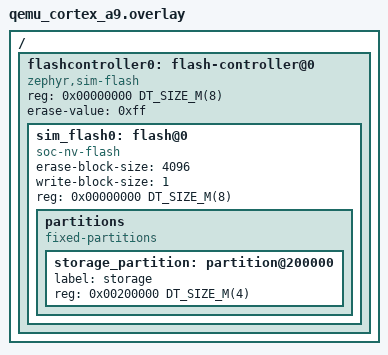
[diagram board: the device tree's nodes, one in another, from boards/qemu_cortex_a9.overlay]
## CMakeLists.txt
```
# SPDX-License-Identifier: GPL-3.0-or-later
# The Zephyr test program: the platform layer's conformance suite and the 615A engine tests,
# run by Catch2 on Zephyr. Built with west or cmake as any Zephyr application is, for native_sim
# in CI (docs/building.md, docs/testing.md); this is the Zephyr counterpart of the
# adl_platform_tests and adl_engine_tests programs of tests/CMakeLists.txt, and runs the same
# source files:
#
#   west build -b native_sim/native/64 tests/platform/zephyr -- -DZEPHYR_EXTRA_MODULES=$PWD
#
# The repository is a Zephyr module (zephyr/module.yml) that builds the platform layer and the
# libraries; this application supplies Catch2, a main, and the board's file system.
cmake_minimum_required(VERSION 3.20.0)

get_filename_component(ADL_REPO_ROOT "${CMAKE_CURRENT_LIST_DIR}/../../.." ABSOLUTE)
list(APPEND ZEPHYR_EXTRA_MODULES "${ADL_REPO_ROOT}")

find_package(Zephyr REQUIRED HINTS $ENV{ZEPHYR_BASE})
project(adl_zephyr_tests LANGUAGES C CXX)

# Catch2, the version the vcpkg baseline of the other platforms resolves to. A source tree can
# be named with -DFETCHCONTENT_SOURCE_DIR_CATCH2=<dir> for a build without network access.
include(FetchContent)
FetchContent_Declare(Catch2
    URL https://github.com/catchorg/Catch2/archive/refs/tags/v3.15.3.tar.gz
    URL_HASH SHA256=b0299ae552918220a7a6e21e7de5b714777f4e8c883fb70c4bb23fe01df8c6e3
    DOWNLOAD_EXTRACT_TIMESTAMP TRUE)
set(CATCH_INSTALL_DOCS OFF CACHE BOOL "" FORCE)
set(CATCH_INSTALL_EXTRAS OFF CACHE BOOL "" FORCE)
set(CATCH_DEVELOPMENT_BUILD OFF CACHE BOOL "" FORCE)
FetchContent_MakeAvailable(Catch2)

# Catch2 is built with Zephyr's flags like everything else (on a board those are the
# architecture's, not the host compiler's defaults), and where there is no host operating system
# under Zephyr (anything but native_sim) without Catch2's POSIX signal handlers.
target_link_libraries(Catch2 PRIVATE zephyr_interface)
if(NOT CONFIG_ARCH_POSIX)
    target_compile_definitions(Catch2 PUBLIC CATCH_CONFIG_NO_POSIX_SIGNALS)
endif()

# What the engine tests need beyond the module's libraries: the sample loads and the second
# TFTP implementation the simulated target is written with.
list(PREPEND CMAKE_MODULE_PATH "${ADL_REPO_ROOT}/cmake")
add_subdirectory("${ADL_REPO_ROOT}/libs/samples" adl_samples)
add_subdirectory("${ADL_REPO_ROOT}/libs/arinc615a_mini" adl_arinc615a_mini)

# Zephyr's flags for them, as the module gives its libraries (-std=c++23 in particular).
foreach(_lib IN ITEMS adl_samples adl_arinc615a_mini)
    target_link_libraries(${_lib} PRIVATE zephyr_interface)
    if(NOT CONFIG_ADL_WARNINGS_AS_ERRORS)
        target_link_libraries(${_lib} PRIVATE adl_zephyr_tolerant)
    endif()
endforeach()

# The sources and include directories the RTOS test programs share.
include("${ADL_REPO_ROOT}/tests/platform/rtos_support/test_sources.cmake")

target_sources(app PRIVATE
    src/main.cpp
    src/stack_storage_test.cpp
    ${ADL_RTOS_PLATFORM_TEST_SOURCES}
    ${ADL_RTOS_ENGINE_TEST_SOURCES})
target_include_directories(app PRIVATE ${ADL_RTOS_TEST_INCLUDES})
target_compile_definitions(app PRIVATE "ADL_TEST_SCRATCH_ROOT=\"/lfs\"")

target_link_libraries(app PRIVATE
    Catch2::Catch2
    adl::platform
    adl::arinc615a_runner
    adl::arinc615a
    adl::arinc665
    adl::arinc615a_mini
    adl::samples)
```

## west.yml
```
# The Zephyr workspace the native_sim test program is built in (tests/platform/zephyr,
# docs/building.md). `west init -l --mf tests/platform/zephyr/west.yml .` in the repository
# makes the directory above it the workspace; `west update` fetches Zephyr at the version the
# program is verified with, and only the modules it needs.
manifest:
  remotes:
    - name: zephyrproject-rtos
      url-base: https://github.com/zephyrproject-rtos
  projects:
    - name: zephyr
      remote: zephyrproject-rtos
      revision: v4.4.2
      import:
        name-allowlist:
          - cmsis      # Cortex-A (the qemu_cortex_a9 suite run); cmsis_6 is Cortex-M
          - cmsis_6
          - littlefs
  self:
    path: arinc-data-loader
```

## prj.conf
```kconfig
# C++23 with the host's standard library (native_sim links the host's libstdc++); Catch2 needs
# exceptions and RTTI.
CONFIG_CPP=y
CONFIG_STD_CPP23=y
CONFIG_REQUIRES_FULL_LIBCPP=y
CONFIG_CPP_EXCEPTIONS=y
CONFIG_CPP_RTTI=y

# Catch2 runs on the main thread, and the 615A engine tests build large buffers on it.
CONFIG_MAIN_STACK_SIZE=262144
CONFIG_HEAP_MEM_POOL_SIZE=4194304

# The platform layer under test.
CONFIG_ADL_PLATFORM=y
CONFIG_ADL_WARNINGS_AS_ERRORS=y
CONFIG_ADL_HEAP_BYTES=2097152
CONFIG_DYNAMIC_THREAD_ALLOC=y
CONFIG_ZVFS_POLL_MAX=64

# Files: littlefs on the simulated flash, mounted at /lfs by main.cpp.
CONFIG_FLASH=y
CONFIG_FLASH_MAP=y
CONFIG_FILE_SYSTEM=y
CONFIG_FILE_SYSTEM_MKFS=y
CONFIG_FILE_SYSTEM_LITTLEFS=y
CONFIG_FS_LITTLEFS_NUM_FILES=16
CONFIG_FS_LITTLEFS_NUM_DIRS=8
CONFIG_FS_LITTLEFS_CACHE_SIZE=512
CONFIG_FS_LITTLEFS_READ_SIZE=64
CONFIG_FS_LITTLEFS_PROG_SIZE=64
CONFIG_FS_LITTLEFS_LOOKAHEAD_SIZE=128
CONFIG_FS_LITTLEFS_FC_HEAP_SIZE=65536

# Network: Zephyr's own IPv4/UDP stack over its loopback interface, so that the tests need no
# tap device and no privilege. A 65468 byte datagram is one loopback packet.
CONFIG_NETWORKING=y
CONFIG_NET_IPV4=y
CONFIG_NET_IPV6=n
CONFIG_NET_UDP=y
CONFIG_NET_TCP=n
CONFIG_NET_DRIVERS=y
CONFIG_NET_LOOPBACK=y
CONFIG_NET_LOOPBACK_MTU=65535
CONFIG_NET_SOCKETS=y
CONFIG_NET_MAX_CONTEXTS=32
CONFIG_NET_MAX_CONN=32
CONFIG_NET_PKT_RX_COUNT=128
CONFIG_NET_PKT_TX_COUNT=128
CONFIG_NET_BUF_DATA_SIZE=1024
CONFIG_NET_BUF_RX_COUNT=600
CONFIG_NET_BUF_TX_COUNT=600
CONFIG_NET_LOG=n
```

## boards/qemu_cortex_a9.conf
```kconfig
# A Cortex-A9 under QEMU, built with the Zephyr SDK's GCC and picolibc: the same program as on
# native_sim, on a real architecture and C library.
CONFIG_PICOLIBC=y
CONFIG_COMMON_LIBC_MALLOC_ARENA_SIZE=33554432
CONFIG_TEST_RANDOM_GENERATOR=y
# GCC 14 at -O2 warns in the libraries (-Wnull-dereference on an inlined allocation).
CONFIG_ADL_WARNINGS_AS_ERRORS=n
# Catch2 and libstdc++'s streams ask the C library for open, read, write, fstat, gettimeofday...:
# Zephyr's POSIX layer answers.
CONFIG_POSIX_API=y
# The board runs with its MMU on, and the kernel's virtual address space (8 MB by default) has to
# hold the whole image: this one is 26 MB, mostly buffers, and without room device mappings panic
# before the console is up.
CONFIG_KERNEL_VM_SIZE=0x8000000
```

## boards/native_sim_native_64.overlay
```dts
/* The flash behind the test file system. native_sim's own is 2 MB with a 16 KB storage
 * partition; the conformance suite writes files of 300 KB, so the flash is made 8 MB and
 * the storage partition 4 MB of it. */

/delete-node/ &storage_partition;

&flashcontroller0 {
	reg = <0x00000000 DT_SIZE_M(8)>;
};

&flash0 {
	reg = <0x00000000 DT_SIZE_M(8)>;

	partitions {
		storage_partition: partition@200000 {
			label = "storage";
			reg = <0x00200000 DT_SIZE_M(4)>;
		};
	};
};
```

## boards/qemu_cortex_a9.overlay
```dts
/* A flash behind the test file system: Zephyr's flash simulator, a RAM array, 8 MB with a 4 MB
 * storage partition, as native_sim has (this board has no flash of its own). */

/ {
	flashcontroller0: flash-controller@0 {
		compatible = "zephyr,sim-flash";
		reg = <0x00000000 DT_SIZE_M(8)>;

		#address-cells = <1>;
		#size-cells = <1>;
		erase-value = <0xff>;

		sim_flash0: flash@0 {
			status = "okay";
			compatible = "soc-nv-flash";
			erase-block-size = <4096>;
			write-block-size = <1>;
			reg = <0x00000000 DT_SIZE_M(8)>;

			partitions {
				compatible = "fixed-partitions";
				#address-cells = <1>;
				#size-cells = <1>;

				storage_partition: partition@200000 {
					label = "storage";
					reg = <0x00200000 DT_SIZE_M(4)>;
				};
			};
		};
	};
};
```

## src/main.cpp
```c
// SPDX-License-Identifier: GPL-3.0-or-later
// The Zephyr test program: Catch2 run on Zephyr's main thread, over the real platform layer
// (libs/platform/zephyr) on whatever board the program is built for. CI builds it for
// native_sim, where Zephyr's kernel, network stack and file system run as a host process.
//
// Before Catch2 starts, the file system the conformance suite writes to is made and mounted:
// littlefs on the board's storage partition at /lfs, freshly formatted so that a run does not
// meet the files of the last. Catch2's arguments come from the environment variable
// ADL_CATCH_ARGS (a native_sim process has an environment and Zephyr's main has no argv):
//
//     ADL_CATCH_ARGS="[conformance] --durations yes" ./zephyr.exe

#include <zephyr/fs/fs.h>
#include <zephyr/fs/littlefs.h>
#include <zephyr/kernel.h>
#include <zephyr/storage/flash_map.h>

#include <catch2/catch_session.hpp>

#include <cstdio>
#include <cstdlib>
#include <string>
#include <vector>

FS_LITTLEFS_DECLARE_DEFAULT_CONFIG(scratch_storage);

namespace
{

fs_mount_t scratch_mount;

[[nodiscard]] bool mount_scratch_file_system()
{
    const auto partition = static_cast<uintptr_t>(DT_FIXED_PARTITION_ID(DT_NODELABEL(storage_partition)));
    if (const int error = fs_mkfs(FS_LITTLEFS, partition, &scratch_storage, 0); error != 0)
    {
        std::printf("fs_mkfs failed: %d\n", error);
        return false;
    }
    scratch_mount.type = FS_LITTLEFS;
    scratch_mount.mnt_point = "/lfs";
    scratch_mount.fs_data = &scratch_storage;
    scratch_mount.storage_dev = reinterpret_cast<void*>(partition);
    if (const int error = fs_mount(&scratch_mount); error != 0)
    {
        std::printf("fs_mount failed: %d\n", error);
        return false;
    }
    return true;
}

// Splits the environment variable on blanks; empty when it is not set.
[[nodiscard]] std::vector<std::string> catch_arguments()
{
    std::vector<std::string> arguments{"adl_zephyr_tests"};
    const char* text = std::getenv("ADL_CATCH_ARGS");
    if (text == nullptr)
    {
        return arguments;
    }
    std::string current;
    for (const char* c = text;; ++c)
    {
        if (*c == ' ' || *c == '\0')
        {
            if (!current.empty())
            {
                arguments.push_back(std::move(current));
                current.clear();
            }
            if (*c == '\0')
            {
                break;
            }
        }
        else
        {
            current.push_back(*c);
        }
    }
    return arguments;
}

} // namespace

int main()
{
    int status = 2;
    if (mount_scratch_file_system())
    {
        const std::vector<std::string> arguments = catch_arguments();
        std::vector<const char*> argv;
        for (const std::string& argument : arguments)
        {
            argv.push_back(argument.c_str());
        }
        Catch::Session session;
        status = session.run(static_cast<int>(argv.size()), argv.data());
    }
    std::fflush(stdout);
    // A native_sim process ends when it is told to, with the code the harness reads; on a
    // board there is nowhere to exit to, and this is the end of the program.
    std::exit(status);
}
```

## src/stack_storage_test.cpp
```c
// A test only Zephyr can run: a thread on a stack the caller made. The conformance suite spawns
// threads with the platform's stacks (dynamic); a platform that must not allocate gives the thread
// its own, as K_KERNEL_STACK_DEFINE makes it, and the port has to use it as it is.

#include "adl/platform/host.hpp"

#include <zephyr/kernel.h>

#include <catch2/catch_test_macros.hpp>

#include <atomic>
#include <cstddef>

using namespace adl::platform;

namespace
{

K_KERNEL_STACK_DEFINE(caller_stack, 4096);

void count_run(void* argument) noexcept
{
    static_cast<std::atomic<int>*>(argument)->fetch_add(1);
}

} // namespace

TEST_CASE("a thread runs on a stack the caller supplies, again and again", "[platform][zephyr][threads]")
{
    auto host = make_host();
    REQUIRE(host.has_value());

    std::atomic<int> runs{0};
    ThreadSpec spec;
    spec.entry = &count_run;
    spec.argument = &runs;
    spec.stack_storage = {reinterpret_cast<std::byte*>(caller_stack), K_KERNEL_STACK_SIZEOF(caller_stack)};

    // The same storage is used by thread after thread, which only works if a finished thread
    // has really let go of it.
    for (int round = 1; round <= 3; ++round)
    {
        auto thread = (*host)->threads().spawn(spec);
        REQUIRE(thread.has_value());
        REQUIRE((*thread)->join().has_value());
        CHECK(runs.load() == round);
    }
}

TEST_CASE("storage that is not aligned for a stack is refused", "[platform][zephyr][threads]")
{
    auto host = make_host();
    REQUIRE(host.has_value());

    std::atomic<int> runs{0};
    ThreadSpec spec;
    spec.entry = &count_run;
    spec.argument = &runs;
    spec.stack_storage =
        std::span<std::byte>{reinterpret_cast<std::byte*>(caller_stack), K_KERNEL_STACK_SIZEOF(caller_stack)}.subspan(
            1);

    auto thread = (*host)->threads().spawn(spec);
    REQUIRE_FALSE(thread.has_value());
    CHECK(thread.error().code == ErrorCode::invalid_argument);
    CHECK(runs.load() == 0);
}
```
